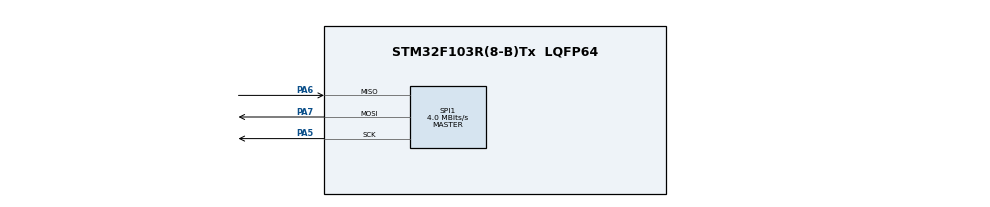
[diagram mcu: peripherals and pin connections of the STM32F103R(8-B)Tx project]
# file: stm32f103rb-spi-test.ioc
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Mcu.Family=STM32F1
Mcu.Name=STM32F103R(8-B)Tx
Mcu.Package=LQFP64
NVIC.PriorityGroup=NVIC_PRIORITYGROUP_4
NVIC.SPI1_IRQn=true\:0\:0\:false\:false\:true\:true\:true
PA5.Mode=Full_Duplex_Master
PA5.Signal=SPI1_SCK
PA6.Mode=Full_Duplex_Master
PA6.Signal=SPI1_MISO
PA7.Mode=Full_Duplex_Master
PA7.Signal=SPI1_MOSI
ProjectManager.HeapSize=0x200
ProjectManager.StackSize=0x400
ProjectManager.TargetToolchain=Makefile
RCC.APB1Freq_Value=8000000
RCC.APB2Freq_Value=8000000
SPI1.CalculateBaudRate=4.0 MBits/s
SPI1.Direction=SPI_DIRECTION_2LINES
SPI1.Mode=SPI_MODE_MASTER
SPI1.VirtualType=VM_MASTER
VP_SYS_VS_ND.Mode=No_Debug
board=custom

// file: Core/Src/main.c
/* USER CODE BEGIN Header */
/**
  ******************************************************************************
  * @file           : main.c
  * @brief          : Main program body
  ******************************************************************************
  * @attention
  *
  * <h2><center>&copy; Copyright (c) 2022 STMicroelectronics.
  * All rights reserved.</center></h2>
  *
  * This software component is licensed by ST under BSD 3-Clause license,
  * the "License"; You may not use this file except in compliance with the
  * License. You may obtain a copy of the License at:
  *                        opensource.org/licenses/BSD-3-Clause
  *
  ******************************************************************************
  */
/* USER CODE END Header */
#include "main.h"
#include "spi.h"
#include "gpio.h"

/* USER CODE BEGIN Includes */
#include <string.h>
/* USER CODE END Includes */

void SystemClock_Config(void);

/* USER CODE BEGIN 0 */
volatile static char test_flag = 0;
void spi_transmit_test_begin(void) { test_flag = 1; }
void spi_transmit_test_end  (void) { test_flag = 0; }
void spi_receive_test_begin (void) { test_flag = 1; }
void spi_receive_test_end   (void) { test_flag = 0; }
/* USER CODE END 0 */

int main(void)
{

  /* MCU Configuration--------------------------------------------------------*/

  /* Reset of all peripherals, Initializes the Flash interface and the Systick. */
  HAL_Init();

  /* Configure the system clock */
  SystemClock_Config();

  /* Initialize all configured peripherals */
  MX_GPIO_Init();
  MX_SPI1_Init();
  /* USER CODE BEGIN 2 */

  char message[] = "A";
  int message_size = strlen(message);

  spi_transmit_test_begin();
  if (HAL_SPI_Transmit(&hspi1, (uint8_t *) message, message_size, HAL_MAX_DELAY) != HAL_OK)
    Error_Handler();
  spi_transmit_test_end();

  spi_receive_test_begin();
  if (HAL_SPI_Receive(&hspi1, (uint8_t *) message, message_size, HAL_MAX_DELAY) != HAL_OK)
    Error_Handler();
  spi_receive_test_end();

  /* USER CODE END 2 */

  /* Infinite loop */
  /* USER CODE BEGIN WHILE */
  while (1)
  {
    HAL_SPI_Transmit(&hspi1, (uint8_t *) message, message_size, HAL_MAX_DELAY);
    /* USER CODE END WHILE */

    /* USER CODE BEGIN 3 */
    HAL_Delay(1000);
  }
  /* USER CODE END 3 */
}

void SystemClock_Config(void)
{
  RCC_OscInitTypeDef RCC_OscInitStruct = {0};
  RCC_ClkInitTypeDef RCC_ClkInitStruct = {0};

  /** Initializes the RCC Oscillators according to the specified parameters
  * in the RCC_OscInitTypeDef structure.
  */
  RCC_OscInitStruct.OscillatorType = RCC_OSCILLATORTYPE_HSI;
  RCC_OscInitStruct.HSIState = RCC_HSI_ON;
  RCC_OscInitStruct.HSICalibrationValue = RCC_HSICALIBRATION_DEFAULT;
  RCC_OscInitStruct.PLL.PLLState = RCC_PLL_NONE;
  if (HAL_RCC_OscConfig(&RCC_OscInitStruct) != HAL_OK)
  {
    Error_Handler();
  }
  /** Initializes the CPU, AHB and APB buses clocks
  */
  RCC_ClkInitStruct.ClockType = RCC_CLOCKTYPE_HCLK|RCC_CLOCKTYPE_SYSCLK
                              |RCC_CLOCKTYPE_PCLK1|RCC_CLOCKTYPE_PCLK2;
  RCC_ClkInitStruct.SYSCLKSource = RCC_SYSCLKSOURCE_HSI;
  RCC_ClkInitStruct.AHBCLKDivider = RCC_SYSCLK_DIV1;
  RCC_ClkInitStruct.APB1CLKDivider = RCC_HCLK_DIV1;
  RCC_ClkInitStruct.APB2CLKDivider = RCC_HCLK_DIV1;

  if (HAL_RCC_ClockConfig(&RCC_ClkInitStruct, FLASH_LATENCY_0) != HAL_OK)
  {
    Error_Handler();
  }
}

void Error_Handler(void)
{
  __disable_irq();
  while (1)
  {
  }
}

/************************ (C) COPYRIGHT STMicroelectronics *****END OF FILE****/
